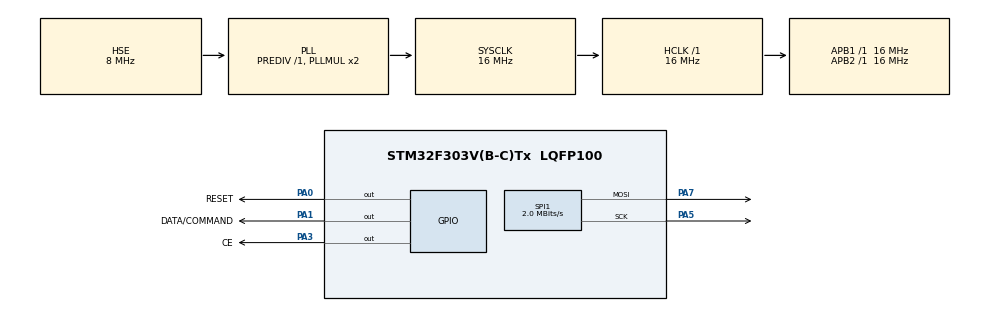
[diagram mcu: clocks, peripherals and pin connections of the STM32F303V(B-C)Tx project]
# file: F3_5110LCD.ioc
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Mcu.Family=STM32F3
Mcu.Name=STM32F303V(B-C)Tx
Mcu.Package=LQFP100
NVIC.PriorityGroup=NVIC_PRIORITYGROUP_4
PA0.GPIO_Label=RESET
PA0.GPIO_PuPd=GPIO_PULLUP
PA0.Signal=GPIO_Output
PA1.GPIO_Label=DATA/COMMAND
PA1.Signal=GPIO_Output
PA3.GPIO_Label=CE
PA3.GPIO_PuPd=GPIO_PULLUP
PA3.Signal=GPIO_Output
PA5.GPIO_PuPd=GPIO_PULLUP
PA5.Mode=TX_Only_Simplex_Unidirect_Master
PA5.Signal=SPI1_SCK
PA7.GPIO_PuPd=GPIO_PULLDOWN
PA7.Mode=TX_Only_Simplex_Unidirect_Master
PA7.Signal=SPI1_MOSI
PF0-OSC_IN.Mode=HSE-External-Clock-Source
PF0-OSC_IN.Signal=RCC_OSC_IN
ProjectManager.TargetToolchain=MDK-ARM V5
RCC.AHBFreq_Value=16000000
RCC.APB1Freq_Value=16000000
RCC.APB1TimFreq_Value=16000000
RCC.APB2Freq_Value=16000000
RCC.APB2TimFreq_Value=16000000
RCC.CortexFreq_Value=16000000
RCC.HCLKFreq_Value=16000000
RCC.HSE_VALUE=8000000
RCC.HSIState=RCC_HSI_ON
RCC.HSI_VALUE=8000000
RCC.LSE_VALUE=32768
RCC.PLLSourceVirtual=RCC_PLLSOURCE_HSE
RCC.SYSCLKFreq_VALUE=16000000
RCC.SYSCLKSourceVirtual=RCC_SYSCLKSOURCE_PLLCLK
RCC.USBFreq_Value=16000000
SPI1.BaudRatePrescaler=SPI_BAUDRATEPRESCALER_8
SPI1.CLKPhase=SPI_PHASE_2EDGE
SPI1.CLKPolarity=SPI_POLARITY_HIGH
SPI1.CalculateBaudRate=2.0 MBits/s
SPI1.DataSize=SPI_DATASIZE_8BIT
SPI1.Mode=SPI_MODE_MASTER
board=F3_5110LCD

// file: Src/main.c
/**
  ******************************************************************************
  * File Name          : main.c
  * Description        : Main program body
  ******************************************************************************
  *
  * COPYRIGHT(c) 2015 STMicroelectronics
  *
  * Redistribution and use in source and binary forms, with or without modification,
  * are permitted provided that the following conditions are met:
  *   1. Redistributions of source code must retain the above copyright notice,
  *      this list of conditions and the following disclaimer.
  *   2. Redistributions in binary form must reproduce the above copyright notice,
  *      this list of conditions and the following disclaimer in the documentation
  *      and/or other materials provided with the distribution.
  *   3. Neither the name of STMicroelectronics nor the names of its contributors
  *      may be used to endorse or promote products derived from this software
  *      without specific prior written permission.
  *
  * THIS SOFTWARE IS PROVIDED BY THE COPYRIGHT HOLDERS AND CONTRIBUTORS "AS IS"
  * AND ANY EXPRESS OR IMPLIED WARRANTIES, INCLUDING, BUT NOT LIMITED TO, THE
  * IMPLIED WARRANTIES OF MERCHANTABILITY AND FITNESS FOR A PARTICULAR PURPOSE ARE
  * DISCLAIMED. IN NO EVENT SHALL THE COPYRIGHT HOLDER OR CONTRIBUTORS BE LIABLE
  * FOR ANY DIRECT, INDIRECT, INCIDENTAL, SPECIAL, EXEMPLARY, OR CONSEQUENTIAL
  * DAMAGES (INCLUDING, BUT NOT LIMITED TO, PROCUREMENT OF SUBSTITUTE GOODS OR
  * SERVICES; LOSS OF USE, DATA, OR PROFITS; OR BUSINESS INTERRUPTION) HOWEVER
  * CAUSED AND ON ANY THEORY OF LIABILITY, WHETHER IN CONTRACT, STRICT LIABILITY,
  * OR TORT (INCLUDING NEGLIGENCE OR OTHERWISE) ARISING IN ANY WAY OUT OF THE USE
  * OF THIS SOFTWARE, EVEN IF ADVISED OF THE POSSIBILITY OF SUCH DAMAGE.
  *
  ******************************************************************************
  */
#include "stm32f3xx_hal.h"
#include "spi.h"
#include "gpio.h"

/* USER CODE BEGIN Includes */
#include "lcd5110.h"

/* USER CODE END Includes */

/* USER CODE BEGIN PV */
/* Private variables ---------------------------------------------------------*/

/* USER CODE END PV */

void SystemClock_Config(void);

/* USER CODE BEGIN PFP */
/* Private function prototypes -----------------------------------------------*/

/* USER CODE END PFP */

int main(void)
{

  /* MCU Configuration----------------------------------------------------------*/

  /* Reset of all peripherals, Initializes the Flash interface and the Systick. */
  HAL_Init();

  /* Configure the system clock */
  SystemClock_Config();

  /* Initialize all configured peripherals */
  MX_GPIO_Init();
  MX_SPI1_Init();

  /* USER CODE BEGIN 2 */
	lcd_init();
	lcd_clear();
	lcd_set_inverse(0);

	uint8_t s[]="ABCDEFGHJKLMNOPQRSTUVWXYZ";
	lcd_string(s);

	/* USER CODE END 2 */

  /* Infinite loop */
  while (1)
  {

  }

}

/** System Clock Configuration
*/
void SystemClock_Config(void)
{

  RCC_OscInitTypeDef RCC_OscInitStruct;
  RCC_ClkInitTypeDef RCC_ClkInitStruct;

  RCC_OscInitStruct.OscillatorType = RCC_OSCILLATORTYPE_HSE;
  RCC_OscInitStruct.HSEState = RCC_HSE_BYPASS;
  RCC_OscInitStruct.HSEPredivValue = RCC_HSE_PREDIV_DIV1;
  RCC_OscInitStruct.PLL.PLLState = RCC_PLL_ON;
  RCC_OscInitStruct.PLL.PLLSource = RCC_PLLSOURCE_HSE;
  RCC_OscInitStruct.PLL.PLLMUL = RCC_PLL_MUL2;
  HAL_RCC_OscConfig(&RCC_OscInitStruct);

  RCC_ClkInitStruct.ClockType = RCC_CLOCKTYPE_SYSCLK;
  RCC_ClkInitStruct.SYSCLKSource = RCC_SYSCLKSOURCE_PLLCLK;
  RCC_ClkInitStruct.AHBCLKDivider = RCC_SYSCLK_DIV1;
  RCC_ClkInitStruct.APB1CLKDivider = RCC_HCLK_DIV1;
  RCC_ClkInitStruct.APB2CLKDivider = RCC_HCLK_DIV1;
  HAL_RCC_ClockConfig(&RCC_ClkInitStruct, FLASH_LATENCY_0);

  HAL_SYSTICK_Config(HAL_RCC_GetHCLKFreq()/1000);

  HAL_SYSTICK_CLKSourceConfig(SYSTICK_CLKSOURCE_HCLK);

  /* SysTick_IRQn interrupt configuration */
  HAL_NVIC_SetPriority(SysTick_IRQn, 0, 0);
}

/************************ (C) COPYRIGHT STMicroelectronics *****END OF FILE****/
